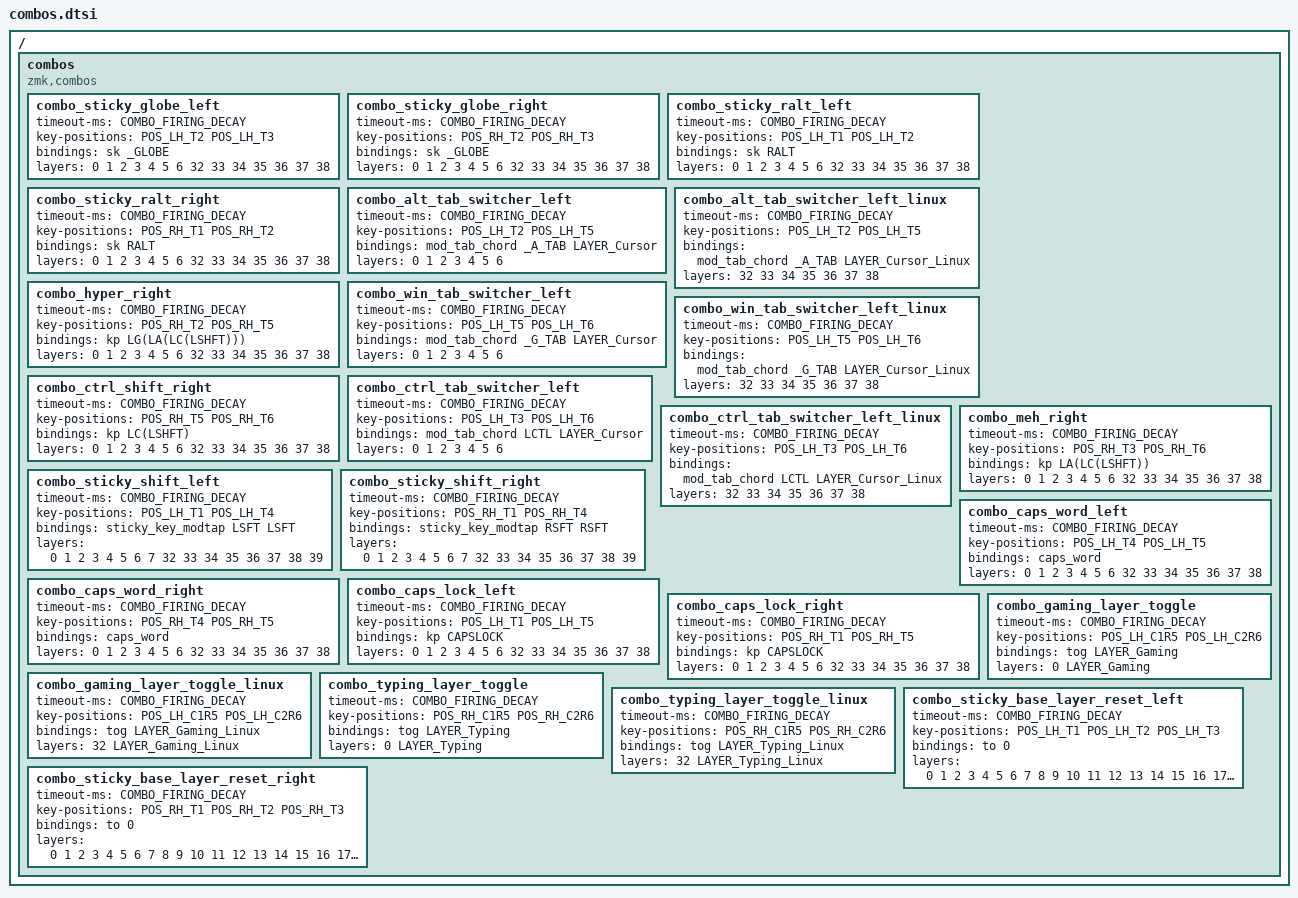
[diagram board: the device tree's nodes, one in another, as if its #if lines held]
/ {
    combos {
        compatible = "zmk,combos";

        //
        // COMBO_FIRING_DECAY defines how much time you have left (milliseconds)
        // after pressing the first key in a ZMK combo to finish the whole chord.
        //
        #ifndef COMBO_FIRING_DECAY
        #define COMBO_FIRING_DECAY 50
        #endif

  // T2+T3

  combo_sticky_globe_left {
    timeout-ms = <COMBO_FIRING_DECAY>;
    key-positions = <POS_LH_T2 POS_LH_T3>;
    bindings = <&sk _GLOBE>;
    layers = <0 1 2 3 4 5 6 32 33 34 35 36 37 38>;
  };

  combo_sticky_globe_right {
    timeout-ms = <COMBO_FIRING_DECAY>;
    key-positions = <POS_RH_T2 POS_RH_T3>;
    bindings = <&sk _GLOBE>;
    layers = <0 1 2 3 4 5 6 32 33 34 35 36 37 38>;
  };

  // T1+T2

  combo_sticky_ralt_left {
    timeout-ms = <COMBO_FIRING_DECAY>;
    key-positions = <POS_LH_T1 POS_LH_T2>;
    bindings = <&sk RALT>;
    layers = <0 1 2 3 4 5 6 32 33 34 35 36 37 38>;
  };

  combo_sticky_ralt_right {
    timeout-ms = <COMBO_FIRING_DECAY>;
    key-positions = <POS_RH_T1 POS_RH_T2>;
    bindings = <&sk RALT>;
    layers = <0 1 2 3 4 5 6 32 33 34 35 36 37 38>;
  };

  // T2+T5
  #if defined(_A_TAB) && defined(LAYER_Cursor)
  combo_alt_tab_switcher_left {
    timeout-ms = <COMBO_FIRING_DECAY>;
    key-positions = <POS_LH_T2 POS_LH_T5>;
    bindings = <&mod_tab_chord _A_TAB LAYER_Cursor>;
    layers = <0 1 2 3 4 5 6>;
  };
  #endif
  #if defined(_A_TAB) && defined(LAYER_Cursor_Linux)
  combo_alt_tab_switcher_left_linux {
    timeout-ms = <COMBO_FIRING_DECAY>;
    key-positions = <POS_LH_T2 POS_LH_T5>;
    bindings = <&mod_tab_chord _A_TAB LAYER_Cursor_Linux>;
    layers = <32 33 34 35 36 37 38>;
  };
  #endif

  combo_hyper_right {
    timeout-ms = <COMBO_FIRING_DECAY>;
    key-positions = <POS_RH_T2 POS_RH_T5>;
    bindings = <&kp LG(LA(LC(LSHFT)))>;
    layers = <0 1 2 3 4 5 6 32 33 34 35 36 37 38>;
  };

  // T5+T6
  #if defined(_G_TAB) && defined(LAYER_Cursor)
  combo_win_tab_switcher_left {
    timeout-ms = <COMBO_FIRING_DECAY>;
    key-positions = <POS_LH_T5 POS_LH_T6>;
    bindings = <&mod_tab_chord _G_TAB LAYER_Cursor>;
    layers = <0 1 2 3 4 5 6>;
  };
  #endif
  #if defined(_G_TAB) && defined(LAYER_Cursor_Linux)
  combo_win_tab_switcher_left_linux {
    timeout-ms = <COMBO_FIRING_DECAY>;
    key-positions = <POS_LH_T5 POS_LH_T6>;
    bindings = <&mod_tab_chord _G_TAB LAYER_Cursor_Linux>;
    layers = <32 33 34 35 36 37 38>;
  };
  #endif

  combo_ctrl_shift_right {
    timeout-ms = <COMBO_FIRING_DECAY>;
    key-positions = <POS_RH_T5 POS_RH_T6>;
    bindings = <&kp LC(LSHFT)>;
    layers = <0 1 2 3 4 5 6 32 33 34 35 36 37 38>;
  };

  // T3+T6

  combo_ctrl_tab_switcher_left {
    timeout-ms = <COMBO_FIRING_DECAY>;
    key-positions = <POS_LH_T3 POS_LH_T6>;
    bindings = <&mod_tab_chord LCTL LAYER_Cursor>;
    layers = <0 1 2 3 4 5 6>;
  };

  #ifdef LAYER_Cursor_Linux
  combo_ctrl_tab_switcher_left_linux {
    timeout-ms = <COMBO_FIRING_DECAY>;
    key-positions = <POS_LH_T3 POS_LH_T6>;
    bindings = <&mod_tab_chord LCTL LAYER_Cursor_Linux>;
    layers = <32 33 34 35 36 37 38>;
  };
  #endif

  combo_meh_right {
    timeout-ms = <COMBO_FIRING_DECAY>;
    key-positions = <POS_RH_T3 POS_RH_T6>;
    bindings = <&kp LA(LC(LSHFT))>;
    layers = <0 1 2 3 4 5 6 32 33 34 35 36 37 38>;
  };

  // T1+T4

  combo_sticky_shift_left {
    timeout-ms = <COMBO_FIRING_DECAY>;
    key-positions = <POS_LH_T1 POS_LH_T4>;
    bindings = <&sticky_key_modtap LSFT LSFT>;
    layers = <0 1 2 3 4 5 6 7 32 33 34 35 36 37 38 39>;
  };

  combo_sticky_shift_right {
    timeout-ms = <COMBO_FIRING_DECAY>;
    key-positions = <POS_RH_T1 POS_RH_T4>;
    bindings = <&sticky_key_modtap RSFT RSFT>;
    layers = <0 1 2 3 4 5 6 7 32 33 34 35 36 37 38 39>;
  };

  // T4+T5

  combo_caps_word_left {
    timeout-ms = <COMBO_FIRING_DECAY>;
    key-positions = <POS_LH_T4 POS_LH_T5>;
    bindings = <&caps_word>;
    layers = <0 1 2 3 4 5 6 32 33 34 35 36 37 38>;
  };

  combo_caps_word_right {
    timeout-ms = <COMBO_FIRING_DECAY>;
    key-positions = <POS_RH_T4 POS_RH_T5>;
    bindings = <&caps_word>;
    layers = <0 1 2 3 4 5 6 32 33 34 35 36 37 38>;
  };

  // T1+T5

  combo_caps_lock_left {
    timeout-ms = <COMBO_FIRING_DECAY>;
    key-positions = <POS_LH_T1 POS_LH_T5>;
    bindings = <&kp CAPSLOCK>;
    layers = <0 1 2 3 4 5 6 32 33 34 35 36 37 38>;
  };

  combo_caps_lock_right {
    timeout-ms = <COMBO_FIRING_DECAY>;
    key-positions = <POS_RH_T1 POS_RH_T5>;
    bindings = <&kp CAPSLOCK>;
    layers = <0 1 2 3 4 5 6 32 33 34 35 36 37 38>;
  };

  // C1R5+C2R6
  #ifdef LAYER_Gaming
  combo_gaming_layer_toggle {
    timeout-ms = <COMBO_FIRING_DECAY>;
    key-positions = <POS_LH_C1R5 POS_LH_C2R6>;
    bindings = <&tog LAYER_Gaming>;
    layers = <0 LAYER_Gaming>;
  };
  #endif
  #ifdef LAYER_Gaming_Linux
  combo_gaming_layer_toggle_linux {
    timeout-ms = <COMBO_FIRING_DECAY>;
    key-positions = <POS_LH_C1R5 POS_LH_C2R6>;
    bindings = <&tog LAYER_Gaming_Linux>;
    layers = <32 LAYER_Gaming_Linux>;
  };
  #endif
  #ifdef LAYER_Typing
  combo_typing_layer_toggle {
    timeout-ms = <COMBO_FIRING_DECAY>;
    key-positions = <POS_RH_C1R5 POS_RH_C2R6>;
    bindings = <&tog LAYER_Typing>;
    layers = <0 LAYER_Typing>;
  };
  #endif
  #ifdef LAYER_Typing_Linux
  combo_typing_layer_toggle_linux {
    timeout-ms = <COMBO_FIRING_DECAY>;
    key-positions = <POS_RH_C1R5 POS_RH_C2R6>;
    bindings = <&tog LAYER_Typing_Linux>;
    layers = <32 LAYER_Typing_Linux>;
  };
  #endif

  // T1+T2+T3

  combo_sticky_base_layer_reset_left {
    timeout-ms = <COMBO_FIRING_DECAY>;
    key-positions = <POS_LH_T1 POS_LH_T2 POS_LH_T3>;
    bindings = <&to 0>;
    layers = <0 1 2 3 4 5 6 7 8 9 10 11 12 13 14 15 16 17 18 19 20 21 22 23 24 25 26 27 28 29 30 31 32 33 34 35 36 37 38 39 40 41 42 43 44 45 46 47 48 49 50 51 52 53 54 55 56 57 58 59 60 61 62 63>;
  };

  combo_sticky_base_layer_reset_right {
    timeout-ms = <COMBO_FIRING_DECAY>;
    key-positions = <POS_RH_T1 POS_RH_T2 POS_RH_T3>;
    bindings = <&to 0>;
    layers = <0 1 2 3 4 5 6 7 8 9 10 11 12 13 14 15 16 17 18 19 20 21 22 23 24 25 26 27 28 29 30 31 32 33 34 35 36 37 38 39 40 41 42 43 44 45 46 47 48 49 50 51 52 53 54 55 56 57 58 59 60 61 62 63>;
  };

    };
};
